# SF32LB58x register map
File version: 1.0
CPU: CM33 r0p1, little endian, MPU, FPU, 3 interrupt priority bits
Registers are 32-bit, read-write, reset 0x0 unless marked. A register's access mark holds for its fields unless they carry their own. Offsets are from the block's base; [hi:lo] are bit positions; {n}, {i} and the like mark numbered series.

## JPEG_ENC
Base 0x40089000
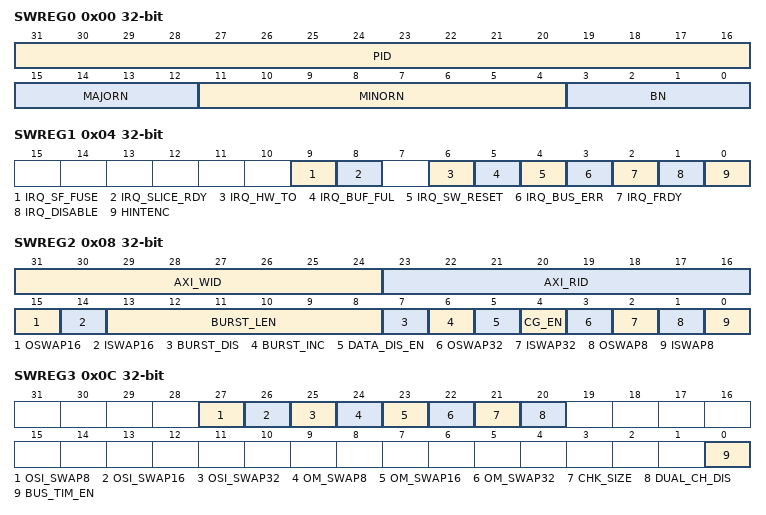
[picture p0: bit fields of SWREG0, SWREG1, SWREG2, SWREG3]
0x00 SWREG0
  [31:16] PID — Product ID
  [15:12] MAJORN — Major number
  [11:4] MINORN — Minor number
  [3:0] BN — Build number defined in synthesis
0x04 SWREG1
  [9] IRQ_SF_FUSE — IRQ stream format fuse status bit. Format disabled by fuse.
  [8] IRQ_SLICE_RDY — IRQ slice ready status bit. Slice is ready but frame encoding continues.
  [6] IRQ_HW_TO — IRQ HW timeout status bit. HW encoding failed.
  [5] IRQ_BUF_FUL — IRQ buffer full status bit. bufferFullInterrupt
  [4] IRQ_SW_RESET — IRQ SW reset status bit.
  [3] IRQ_BUS_ERR — IRQ bus error status bit.
  [2] IRQ_FRDY — IRQ frame ready status bit. Encoder has finished a frame.
  [1] IRQ_DISABLE — IRQ disable. No interrupts from HW. SW must use polling.
  [0] HINTENC — HINTenc Interrupt from HW. SW resets at IRQ handle.
0x08 SWREG2
  [31:24] AXI_WID — AXI Write ID
  [23:16] AXI_RID — AXI Read ID
  [15] OSWAP16 — Enable output stream swap 16-bits
  [14] ISWAP16 — Enable input swap 16-bits
  [13:8] BURST_LEN — Burst length. 0=incremental. 4=max BURST4.8=max BURST8. 16=max BURST16
  [7] BURST_DIS — Disable burst mode for AXI
  [6] BURST_INC — Burst incremental. 1=INCR burst allowed. 0=use SINGLE burst
  [5] DATA_DIS_EN — Enable burst data discard. 2 or 3 long reads are using BURST4
  [4] CG_EN — Enable clock gating
  [3] OSWAP32 — Enable output stream swap 32-bits
  [2] ISWAP32 — Enable input swap 32-bits
  [1] OSWAP8 — Enable output stream swap 8-bits
  [0] ISWAP8 — Enable input swap 8-bits
0x0C SWREG3
  [27] OSI_SWAP8 — Enable output scaled image swap for 8-bits
  [26] OSI_SWAP16 — Enable output scaled image swap for 16-bits
  [25] OSI_SWAP32 — Enable output scaled image swap for 32-bits
  [24] OM_SWAP8 — Enable output MV (MB info) swap for 8-bits
  [23] OM_SWAP16 — Enable output MV (MB info) swap for 16-bits
  [22] OM_SWAP32 — Enable output MV (MB info) swap for 32-bits
  [21] CHK_SIZE — Chunk size for input picture read 0=4 MBs. 1=1 MB
  [20] DUAL_CH_DIS — Disable dual channel AXI. 0=use two channels. 1=use single channel.
  [0] BUS_TIM_EN — Enable MB bus timing info output.
0x14 SWREG5
  [31:0] OS_ADDR — Base address for output stream data
0x18 SWREG6
  [31:0] OC_ADDR — Base address for output control data
0x1C SWREG7
  [31:0] RL_ADDR — Base address for reference luma
0x20 SWREG8
  [31:0] RC_ADDR — Base address for reference chroma
0x24 SWREG9
  [31:0] RECL_ADDR — Base address for reconstructed luma
0x28 SWREG10
  [31:0] RECC_ADDR — Base address for reconstructed chroma
0x2C SWREG11
  [31:0] IPL_ADDR — Base address for input picture luma
0x30 SWREG12
  [31:0] IPCB_ADDR — Base address for input picture cb
0x34 SWREG13
  [31:0] IPCR_ADDR — Base address for input picture cr
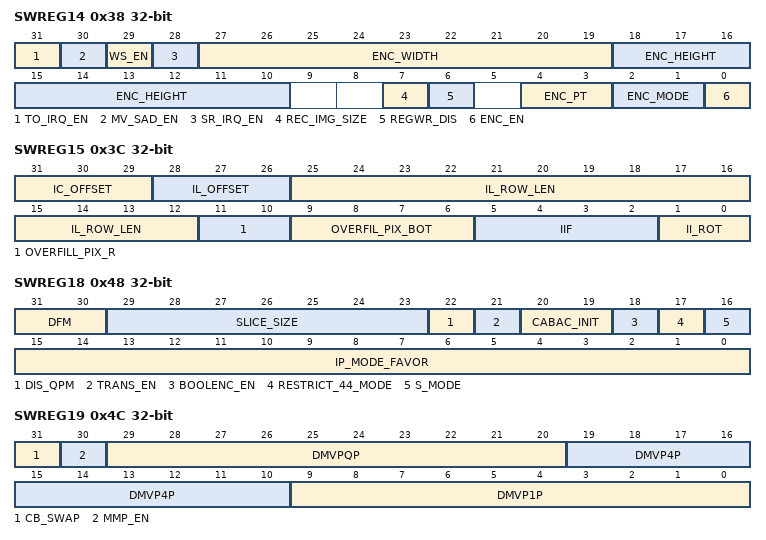
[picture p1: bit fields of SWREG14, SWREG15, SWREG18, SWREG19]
0x38 SWREG14
  [31] TO_IRQ_EN — Enable interrupt for timeout
  [30] MV_SAD_EN — Enable writing MV and SAD of each MB to BaseMvWrite
  [29] WS_EN — Enable writing size of each NAL unit to BaseControl, nalSizeWriteOut
  [28] SR_IRQ_EN — Enable interrupt for slice ready
  [27:19] ENC_WIDTH — Encoded width. lumWidth (macroblocks) H264:[9..255] JPEG:[6..511]
  [18:10] ENC_HEIGHT — Encoded height. lumHeight (macroblocks) H264:[6..255] JPEG:[2..511]
  [7] REC_IMG_SIZE — Size of buffer used when writing reconstructed image. 0=1 MB buffered (write burst for every MB). 1=4 MBs buffered (write burst for every fourth MB)
  [6] REGWR_DIS — Disable writing of reconstructed image. recWriteDisable
  [4:3] ENC_PT — Encoded picture type. frameType. 0=INTER. 1=INTRA(IDR). 2=MVC-INTER. 3=MVC-INTER(ref mod).
  [2:1] ENC_MODE — Encoding mode. streamType. 1=VP8. 2=JPEG. 3=H264
  [0] ENC_EN — Encoder enable
0x3C SWREG15
  [31:29] IC_OFFSET — Input chrominance offset (bytes) [0..7]
  [28:26] IL_OFFSET — Input luminance offset (bytes) [0..7]
  [25:12] IL_ROW_LEN — Input luminance row length. lumWidthSrc (bytes) [96..8192]
  [11:10] OVERFILL_PIX_R — Overfill pixels on right edge of image div4 [0..3]
  [9:6] OVERFIL_PIX_BOT — Overfill pixels on bottom edge of image. YFill. [0..15]
  [5:2] IIF — Input image format. inputFormat. YUV420P/YUV420SP/YUYV422/UYVY422/RGB565/RGB555/RGB444/RGB888/RGB101010/P010SP/P010P
  [1:0] II_ROT — Input image rotation. 0=disabled. 1=90 degrees right. 2=90 degrees left. 3=180 degrees right.
0x40 SWREG16
  [31:0] SRL_ADDR — Base address for second reference luma
0x44 SWREG17
  [31:0] SRC_ADDR — Base address for second reference chroma
0x48 SWREG18
  [31:30] DFM — Deblocking filter mode. 0=enabled. 1=disabled (vp8=simple). 2=disabled on slice borders
  [29:23] SLICE_SIZE — H.264 Slice size. mbRowPerSlice (mb rows) [0..127] 0=one slice per picture
  [22] DIS_QPM — H.264 Disable quarter pixel MVs. disableQuarterPixelMv
  [21] TRANS_EN — H.264 Transform 8x8 enable. High Profile H.264. transform8x8Mode
  [20:19] CABAC_INIT — H.264 CABAC initial IDC. [0..2]
  [18] BOOLENC_EN — H.264 CABAC / VP8 boolenc enable. entropyCodingMode. 0=CAVLC (Baseline Profile H.264). 1=CABAC (Main Profile H.264)
  [17] RESTRICT_44_MODE — H.264 Inter 4x4 mode restriction. restricted4x4Mode
  [16] S_MODE — H.264 Stream mode. byteStream. 0=NAL unit stream. 1=Byte stream
  [15:0] IP_MODE_FAVOR — Intra prediction intra 16x16 mode favor
0x4C SWREG19
  [31] CB_SWAP — Swap order of chroma bytes in semiplanar input format.
  [30] MMP_EN — Enable using more than 1 MV per macroblock.
  [29:20] DMVPQP — Differential MV penalty for 1/4p ME. DMVPenaltyQp
  [19:10] DMVP4P — Differential MV penalty for 4p ME. DMVPenalty4p
  [9:0] DMVP1P — Differential MV penalty for 1p ME. DMVPenalty1p
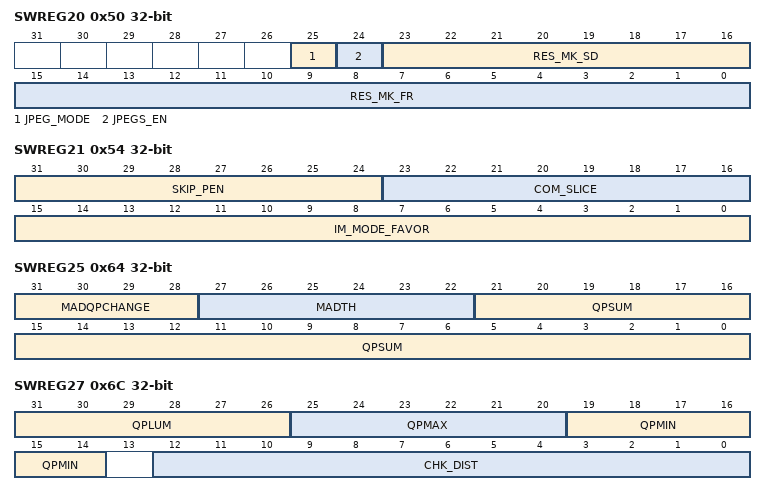
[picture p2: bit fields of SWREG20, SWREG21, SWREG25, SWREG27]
0x50 SWREG20
  [25] JPEG_MODE — JPEG mode. 0=4:2:0 (4lum+2chr blocks/MCU). 1=4:2:2 (2lum+2chr blocks/MCU)
  [24] JPEGS_EN — JPEG slice enable. 0=picture ends with EOI. 1=slice ends with RST
  [23:16] RES_MK_SD — JPEG restart marker interval when slices are disabled (mb rows) [0..255]
  [15:0] RES_MK_FR — JPEG restart marker for first RST. incremented by HW for next RST
0x54 SWREG21
  [31:24] SKIP_PEN — H.264 SKIP macroblock mode / VP8 zero/nearest/near mode penalty
  [23:16] COM_SLICE — H.264 amount of completed slices.
  [15:0] IM_MODE_FAVOR — Inter MB mode favor in intra/inter selection
0x58 SWREG22
  [31:0] SHRM_BITS_MSB — Stream header remainder bits MSB (MSB aligned)
0x5C SWREG23
  [31:0] SHRM_BITS_LSB — Stream header remainder bits LSB (MSB aligned)
0x60 SWREG24
  [31:0] SBUF_LIMIT — Stream buffer limit (64bit addresses) / output stream size (bits). HWStreamDataCount. If limit is reached buffer full IRQ is given.
0x64 SWREG25
  [31:28] MADQPCHANGE — MAD based QP adjustment. madQpChange [-8..7]
  [27:22] MADTH — MAD threshold div256
  [21:0] QPSUM — QP Sum div2 output
0x68 SWREG26
  [31:0] INTRASLC_BM — Intra slice bitmap for slices 64..95. LSB=slice64. MSB=slice95. 1=intra.
0x6C SWREG27
  [31:26] QPLUM — H.264 Initial QP. qpLum [0..51]
  [25:20] QPMAX — H.264 Maximum QP. qpMax [0..51]
  [19:14] QPMIN — H.264 Minimum QP. qpMin [0..51]
  [12:0] CHK_DIST — H.264 Checkpoint distance (mb) 0=disabled [0..8191]
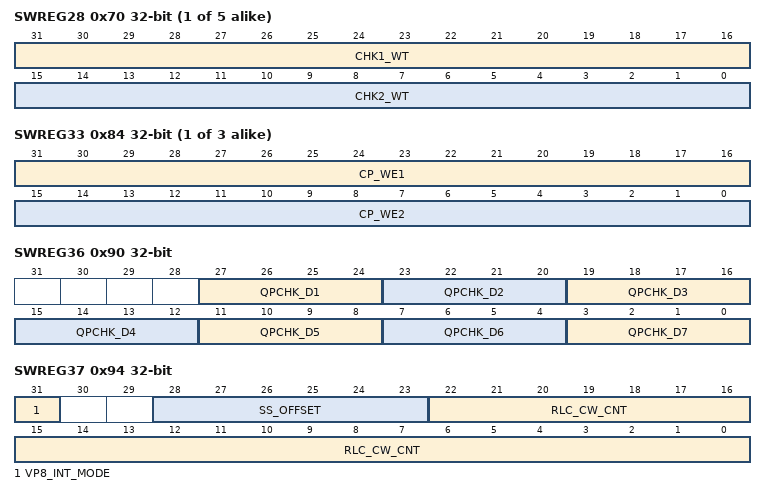
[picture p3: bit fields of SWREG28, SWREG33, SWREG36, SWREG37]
{0x0+4i} SWREG{i} (i=28..32)
  [31:16] CHK{2i-55}_WT — H.264 Checkpoint {2i-55} word target/usage div32 [0..65535]
  [15:0] CHK{2i-54}_WT — H.264 Checkpoint {2i-54} word target/usage div32 [0..65535]
{0x0+4i} SWREG{i} (i=33..35)
  [31:16] CP_WE{2i-65} — H.264 Checkpoint word error {2i-65} div4 [-32768..32767]
  [15:0] CP_WE{2i-64} — H.264 Checkpoint word error {2i-64} div4 [-32768..32767]
0x90 SWREG36
  [31-4n:28-4n] QPCHK_D{n} (n=1..7) — H.264 Checkpoint delta QP {n} [-8..7]
0x94 SWREG37
  [31] VP8_INT_MODE — Mode for VP8 interpolation filter. 0=bicubic. 1=bilinear.
  [28:23] SS_OFFSET — Stream start offset = amount of StrmHdrRem (bits) [0..63]
  [22:0] RLC_CW_CNT — RLC codeword count div4 output. max 255*255*384/4
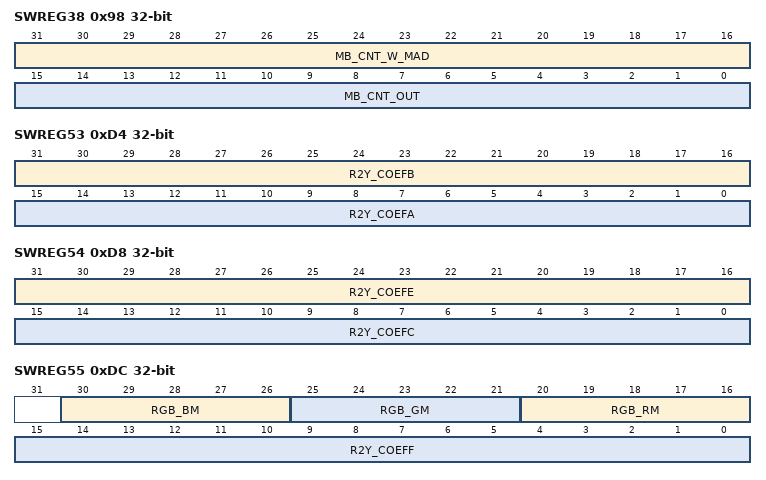
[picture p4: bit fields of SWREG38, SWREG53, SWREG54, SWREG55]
0x98 SWREG38
  [31:16] MB_CNT_W_MAD — Macroblock count with MAD value under threshold output
  [15:0] MB_CNT_OUT — MB count output. max 255*255
0x9C SWREG39
  [31:0] NPL_ADDR — Base address for next pic luminance
0xCC SWREG51
  [31:0] CCT_PT_ADDR — Base address for cabac context tables (H264) or probability tables (VP8)
0xD0 SWREG52
  [31:0] MVO_WR_ADDR — Base address for MV output writing
0xD4 SWREG53
  [31:16] R2Y_COEFB — RGB to YUV conversion coefficient B
  [15:0] R2Y_COEFA — RGB to YUV conversion coefficient A
0xD8 SWREG54
  [31:16] R2Y_COEFE — RGB to YUV conversion coefficient E
  [15:0] R2Y_COEFC — RGB to YUV conversion coefficient C
0xDC SWREG55
  [30:26] RGB_BM — RGB B-component mask MSB bit position [0..31]
  [25:21] RGB_GM — RGB G-component mask MSB bit position [0..31]
  [20:16] RGB_RM — RGB R-component mask MSB bit position [0..31]
  [15:0] R2Y_COEFF — RGB to YUV conversion coefficient F
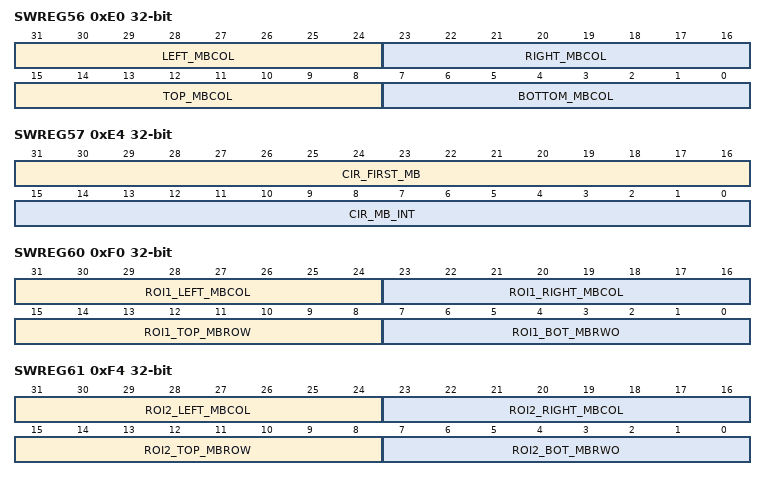
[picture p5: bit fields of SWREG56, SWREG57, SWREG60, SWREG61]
0xE0 SWREG56
  [31:24] LEFT_MBCOL — Intra area left mb column (inside area) [0..255]
  [23:16] RIGHT_MBCOL — Intra area right mb column (outside area) [0..255]
  [15:8] TOP_MBCOL — Intra area top mb row (inside area) [0..255]
  [7:0] BOTTOM_MBCOL — Intra area bottom mb row (outside area) [0..255]
0xE4 SWREG57
  [31:16] CIR_FIRST_MB — CIR first intra mb. 0=disabled [0..65535]
  [15:0] CIR_MB_INT — CIR intra mb interval. 0=disabled [0..65535]
0xE8 SWREG58
  [31:0] INTRASLC_BM — Intra slice bitmap for slices 0..31. LSB=slice0. MSB=slice31. 1=intra.
0xEC SWREG59
  [31:0] INTRASLC_BM — Intra slice bitmap for slices 32..63. LSB=slice32. MSB=slice63. 1=intra.
0xF0 SWREG60
  [31:24] ROI1_LEFT_MBCOL — 1st ROI area left mb column (inside area) qp+=Roi1DeltaQp
  [23:16] ROI1_RIGHT_MBCOL — 1st ROI area right mb column (outside area) qp-=Roi1DeltaQp
  [15:8] ROI1_TOP_MBROW — 1st ROI area top mb row (inside area)
  [7:0] ROI1_BOT_MBRWO — 1st ROI area bottom mb row (outside area)
0xF4 SWREG61
  [31:24] ROI2_LEFT_MBCOL — 2nd ROI area left mb column (inside area) qp+=Roi2DeltaQp
  [23:16] ROI2_RIGHT_MBCOL — 2nd ROI area right mb column (outside area) qp-=Roi2DeltaQp
  [15:8] ROI2_TOP_MBROW — 2nd ROI area top mb row (inside area)
  [7:0] ROI2_BOT_MBRWO — 2nd ROI area bottom mb row (outside area)
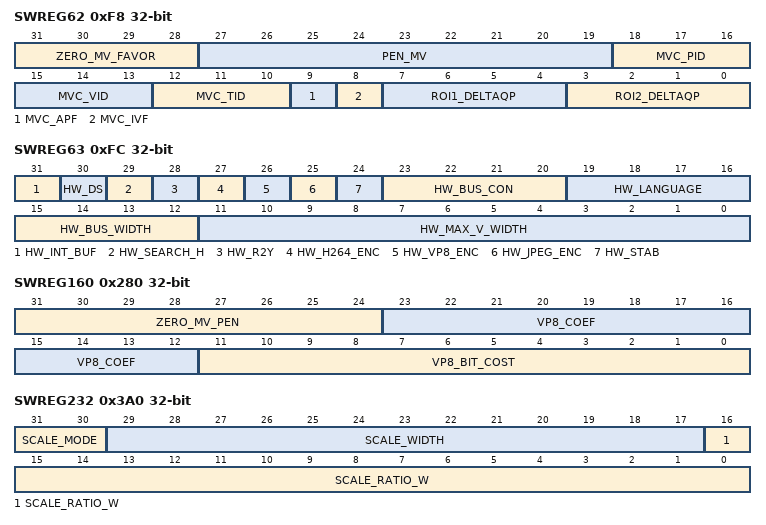
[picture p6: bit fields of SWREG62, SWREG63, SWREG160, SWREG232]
0xF8 SWREG62
  [31:28] ZERO_MV_FAVOR — Zero 16x16 MV favor div2.
  [27:19] PEN_MV — Penalty for using 4x4 MV.
  [18:16] MVC_PID — MVC priority_id [0..7]
  [15:13] MVC_VID — MVC view_id [0..7]
  [12:10] MVC_TID — MVC temporal_id [0..7]
  [9] MVC_APF — MVC anchor_pic_flag. Specifies that the picture is part of an anchor access unit.
  [8] MVC_IVF — MVC inter_view_flag. Specifies that the picture is used for inter-view prediction.
  [7:4] ROI1_DELTAQP — 1st ROI area delta QP. qp = Qp - Roi1DeltaQp [0..15]
  [3:0] ROI2_DELTAQP — 2nd ROI area delta QP. qp = Qp - Roi2DeltaQp [0..15]
0xFC SWREG63
  [31] HW_INT_BUF — HW Chrominance search area internal buffer. 0=not supported. 1=supported.
  [30] HW_DS — Down-scaling supported by HW. 0=not supported. 1=supported
  [29] HW_SEARCH_H — HW search area height. 0=5 MB rows. 1=3 MB rows
  [28] HW_R2Y — RGB to YUV conversion supported by HW. 0=not supported. 1=supported
  [27] HW_H264_ENC — H.264 encoding supported by HW. 0=not supported. 1=supported
  [26] HW_VP8_ENC — VP8 encoding supported by HW. 0=not supported. 1=supported
  [25] HW_JPEG_ENC — JPEG encoding supported by HW. 0=not supported. 1=supported
  [24] HW_STAB — Stabilization supported by HW. 0=not supported. 1=supported
  [23:20] HW_BUS_CON — Bus connection of HW. 1=AHB. 2=OCP. 3=AXI. 4=PCI. 5=AXIAHB. 6=AXIAPB.
  [19:16] HW_LANGUAGE — Synthesis language. 1=vhdl. 2=verilog
  [15:12] HW_BUS_WIDTH — Bus width of HW. 0=32b. 1=64b. 2=128b
  [11:0] HW_MAX_V_WIDTH — Maximum video width supported by HW (pixels)
{0x0+4i} SWREG{i} (i=64..79)
  [31:0] JLQ{i-63} — JPEG luma quantization {i-63}
{0x0+4i} SWREG{i} (i=80..95)
  [31:0] JCQ{i-79} — JPEG chroma quantization {i-79}
0x280 SWREG160
  [31:24] ZERO_MV_PEN — Penalty for using zero-MV in 16x8/8x16/8x8 split
  [23:12] VP8_COEF — VP8 coeff for dmv penalty for intra/inter selection
  [11:0] VP8_BIT_COST — VP8 bit cost of inter type
0x39C SWREG231
  [31:0] DS_ENC_IMG_ADDR — Base address for output of down-scaled encoder image in YUYV 4:2:2 format
0x3A0 SWREG232
  [31:30] SCALE_MODE — Scaling mode. ScalingMode. 0=disabled. 1=scaling only. 2=scale+encode
  [29:17] SCALE_WIDTH — Scaling width of down-scaled image. ScaledWidth. [96..4076]
  [16:0] SCALE_RATIO_W — Scaling ratio for width of down-scaled image. Fixed point integer 1.16.
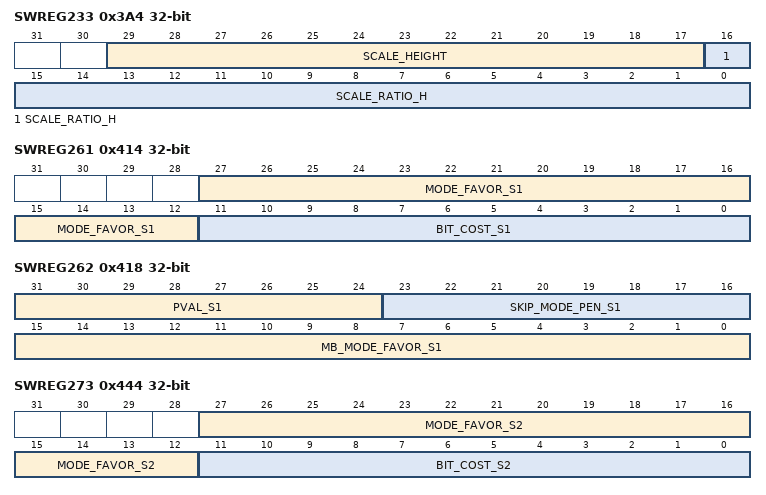
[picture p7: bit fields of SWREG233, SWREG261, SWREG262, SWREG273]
0x3A4 SWREG233
  [29:17] SCALE_HEIGHT — Scaling height of down-scaled image. ScaledHeight. [2..4078]
  [16:0] SCALE_RATIO_H — Scaling ratio for height of down-scaled image. Fixed point integer 1.16.
0x3D0 SWREG244
  [31:0] VP8_3RD_DCT_ADDR — Base address for VP8 3rd DCT partition
0x3D4 SWREG245
  [31:0] VP8_4TH_DCT_ADDR — Base address for VP8 4th DCT partition
0x414 SWREG261
  [27:12] MODE_FAVOR_S1 — Segment 1: Intra 16x16 mode favor in intra 16x16/4x4 selection
  [11:0] BIT_COST_S1 — Segment 1: Bit cost of inter type
0x418 SWREG262
  [31:24] PVAL_S1 — Segment 1: Penalty value for second reference frame zero-mv. VP8 golden / H.264 LTR. [0..255]
  [23:16] SKIP_MODE_PEN_S1 — Segment 1: Skip mode (zero/nearest/near) penalty
  [15:0] MB_MODE_FAVOR_S1 — Segment 1: Inter MB mode favor in intra/inter selection
0x444 SWREG273
  [27:12] MODE_FAVOR_S2 — Segment 2: Intra 16x16 mode favor in intra 16x16/4x4 selection
  [11:0] BIT_COST_S2 — Segment 2: Bit cost of inter type
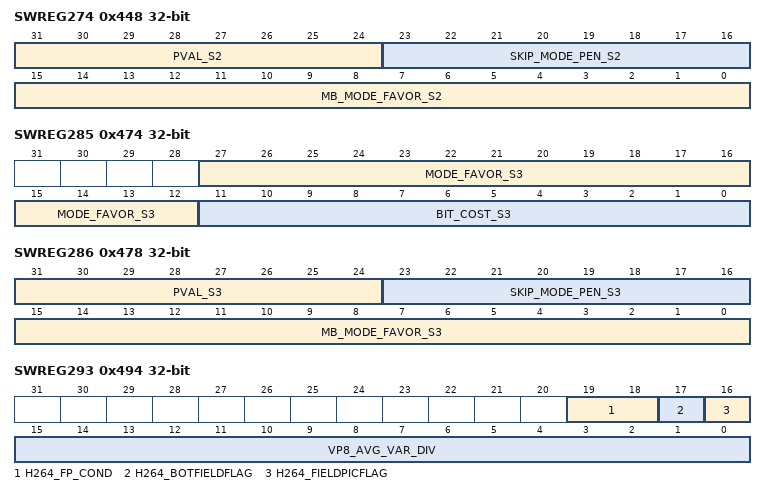
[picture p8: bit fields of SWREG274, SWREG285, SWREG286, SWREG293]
0x448 SWREG274
  [31:24] PVAL_S2 — Segment 2: Penalty value for second reference frame zero-mv. VP8 golden / H.264 LTR. [0..255]
  [23:16] SKIP_MODE_PEN_S2 — Segment 2: Skip mode (zero/nearest/near) penalty
  [15:0] MB_MODE_FAVOR_S2 — Segment 2: Inter MB mode favor in intra/inter selection
0x474 SWREG285
  [27:12] MODE_FAVOR_S3 — Segment 3: Intra 16x16 mode favor in intra 16x16/4x4 selection
  [11:0] BIT_COST_S3 — Segment 3: Bit cost of inter type
0x478 SWREG286
  [31:24] PVAL_S3 — Segment 3: Penalty value for second reference frame zero-mv. VP8 golden / H.264 LTR. [0..255]
  [23:16] SKIP_MODE_PEN_S3 — Segment 3: Skip mode (zero/nearest/near) penalty
  [15:0] MB_MODE_FAVOR_S3 — Segment 3: Inter MB mode favor in intra/inter selection
0x490 SWREG292
  [31:0] VP8_AVG_VAR — VP8 average variance in prev frame
0x494 SWREG293
  [19:18] H264_FP_COND — H.264 Field parity conditions for chroma MV. 0=same parity 1=top/bottom 2=bottom/top
  [17] H264_BOTFIELDFLAG — H.264 BottomFieldFlag. 0=top 1=bottom field
  [16] H264_FIELDPICFLAG — H.264 FieldPicFlag. 0=frame 1=field
  [15:0] VP8_AVG_VAR_DIV — VP8 16384/avgVar in prev frame
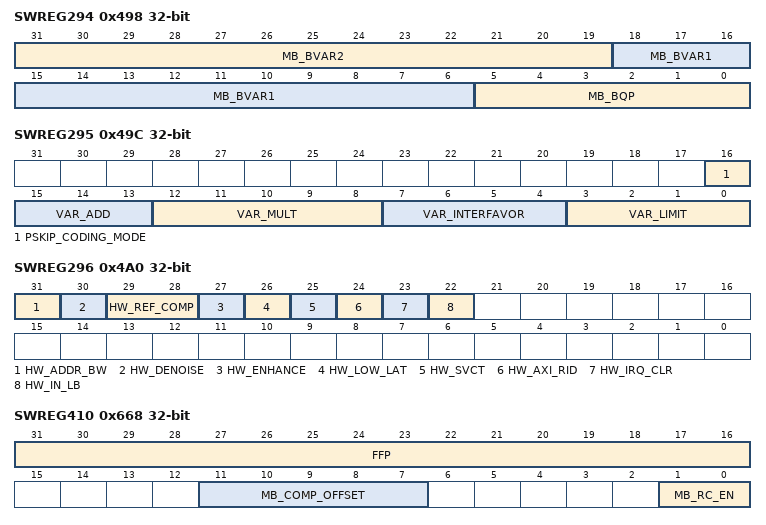
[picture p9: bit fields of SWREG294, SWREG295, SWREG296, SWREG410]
0x498 SWREG294
  [31:19] MB_BVAR2 — Mb boost variance2
  [18:6] MB_BVAR1 — Mb boost variance1
  [5:0] MB_BQP — Mb boost qp
0x49C SWREG295
  [16] PSKIP_CODING_MODE
  [15:13] VAR_ADD — Variance add
  [12:8] VAR_MULT — Variance multiplier
  [7:4] VAR_INTERFAVOR — Variance interFavor
  [3:0] VAR_LIMIT — Variance limit
0x4A0 SWREG296
  [31] HW_ADDR_BW — HW Address bit width. 0=32 bits. 1=64 bits.
  [30] HW_DENOISE — HW Denoise Support.
  [29:28] HW_REF_COMP — HW Reference Compression Support for Luma and Chroma.
  [27] HW_ENHANCE — HW Enhancement for Quality.
  [26] HW_LOW_LAT — HW Low Latency Control.
  [25] HW_SVCT — HW SVCT Support.
  [24] HW_AXI_RID — HW AXI Read ID for Input Support.
  [23] HW_IRQ_CLR — HW IRQ is clear in write-one way.
  [22] HW_IN_LB — HW Input Loopback Support. not support now
0x668 SWREG410
  [31:16] FFP — fractional part of frame qp. .16 format
  [11:7] MB_COMP_OFFSET — offset of MB complexity
  [1:0] MB_RC_EN — MB RC Enable 0 = disable 1 = enable
0x66C SWREG411
  [15:0] MB_GAIN — gain of MB qp delta. 8.8 format
0x670 SWREG412
  [31:0] AVG_MB_COMP — average of MB complexity
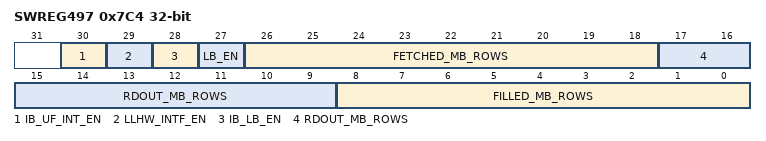
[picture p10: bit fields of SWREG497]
0x7C4 SWREG497
  [30] IB_UF_INT_EN — Enable input Buffer underflow interrupt.
  [29] LLHW_INTF_EN — Low Latency Hardware Interface Enable. Use hardware handshaking.
  [28] IB_LB_EN — Input Buffer Loop Back Enable. valid only when sw_num_mb_rows_per_sync is smaller than frame size.
  [27] LB_EN — Line Buffer Enable
  [26:18] FETCHED_MB_ROWS — The number of MB rows featched by encoder which will introduce HW shakehand happens.
  [17:9] RDOUT_MB_ROWS — The number of MB rows that is already read out from the input buffer
  [8:0] FILLED_MB_ROWS — The number of MB rows that is already filled in the input buffer
0x7C8 SWREG498
  [31:0] LB_OFFSET — Encoder Line Buffer Offset from Base Input Address.
